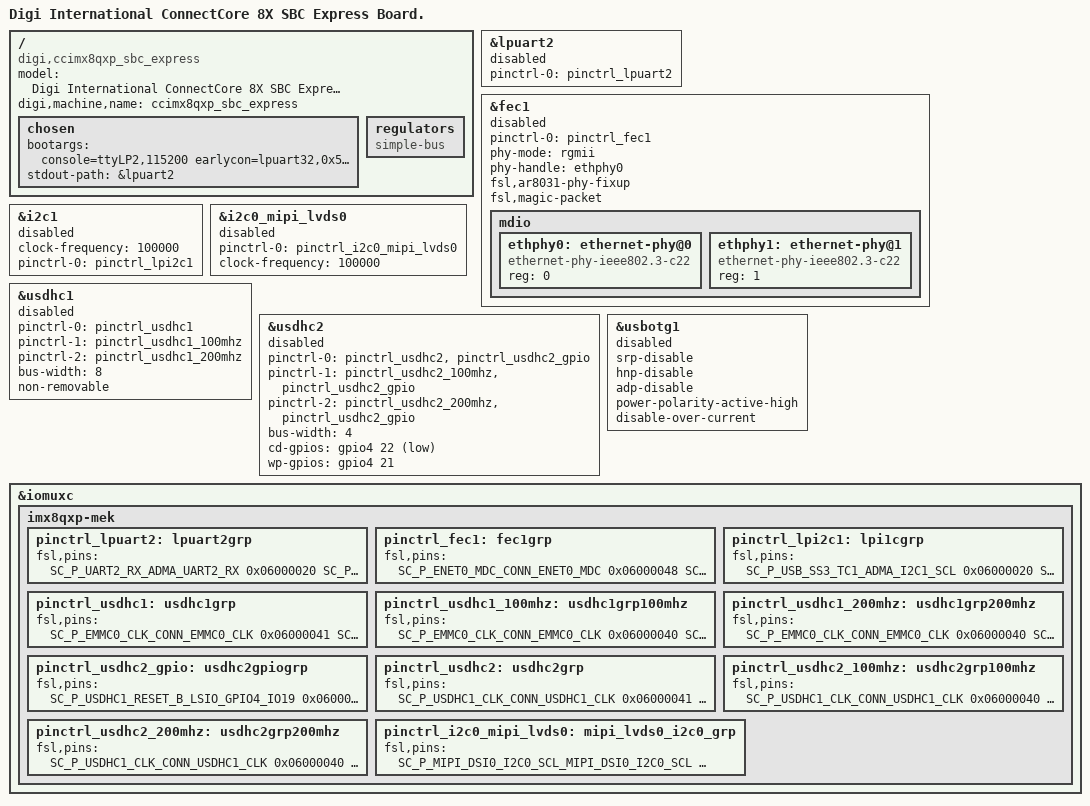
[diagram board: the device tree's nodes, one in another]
/*
 * Copyright 2018 Digi International, Inc.
 *
 * The code contained herein is licensed under the GNU General Public
 * License. You may obtain a copy of the GNU General Public License
 * Version 2 or later at the following locations:
 *
 * http://www.opensource.org/licenses/gpl-license.html
 * http://www.gnu.org/copyleft/gpl.html
 */

/ {
	model = "Digi International ConnectCore 8X SBC Express Board.";
	compatible = "digi,ccimx8qxp_sbc_express", "digi,ccimx8qxp", "fsl,imx8qxp";
	digi,machine,name = "ccimx8qxp_sbc_express";

	chosen {
		bootargs = "console=ttyLP2,115200 earlycon=lpuart32,0x5a080000,115200";
		stdout-path = &lpuart2;
	};

	regulators {
		compatible = "simple-bus";
		#address-cells = <1>;
		#size-cells = <0>;
	};
};

&lpuart2 {
	pinctrl-names = "default";
	pinctrl-0 = <&pinctrl_lpuart2>;
	status = "disabled";
};

&fec1 {
	pinctrl-names = "default";
	pinctrl-0 = <&pinctrl_fec1>;
	phy-mode = "rgmii";
	phy-handle = <&ethphy0>;
	fsl,ar8031-phy-fixup;
	fsl,magic-packet;
	status = "disabled";

	mdio {
		#address-cells = <1>;
		#size-cells = <0>;

		ethphy0: ethernet-phy@0 {
			compatible = "ethernet-phy-ieee802.3-c22";
			reg = <0>;
		};

		ethphy1: ethernet-phy@1 {
			compatible = "ethernet-phy-ieee802.3-c22";
			reg = <1>;
		};
	};
};

&i2c1 {
	#address-cells = <1>;
	#size-cells = <0>;
	clock-frequency = <100000>;
	pinctrl-names = "default";
	pinctrl-0 = <&pinctrl_lpi2c1>;
	status = "disabled";
};

&i2c0_mipi_lvds0 {
	#address-cells = <1>;
	#size-cells = <0>;
	pinctrl-names = "default";
	pinctrl-0 = <&pinctrl_i2c0_mipi_lvds0>;
	clock-frequency = <100000>;
	status = "disabled";
};

&usdhc1 {
	pinctrl-names = "default", "state_100mhz", "state_200mhz";
	pinctrl-0 = <&pinctrl_usdhc1>;
	pinctrl-1 = <&pinctrl_usdhc1_100mhz>;
	pinctrl-2 = <&pinctrl_usdhc1_200mhz>;
	bus-width = <8>;
	non-removable;
	status = "disabled";
};

&usdhc2 {
	pinctrl-names = "default", "state_100mhz", "state_200mhz";
	pinctrl-0 = <&pinctrl_usdhc2>, <&pinctrl_usdhc2_gpio>;
	pinctrl-1 = <&pinctrl_usdhc2_100mhz>, <&pinctrl_usdhc2_gpio>;
	pinctrl-2 = <&pinctrl_usdhc2_200mhz>, <&pinctrl_usdhc2_gpio>;
	bus-width = <4>;
	cd-gpios = <&gpio4 22 GPIO_ACTIVE_LOW>;
	wp-gpios = <&gpio4 21 GPIO_ACTIVE_HIGH>;
	status = "disabled";
};

&usbotg1 {
	srp-disable;
	hnp-disable;
	adp-disable;
	power-polarity-active-high;
	disable-over-current;
	status = "disabled";
};

&iomuxc {
	pinctrl-names = "default";
	imx8qxp-mek {

		pinctrl_lpuart2: lpuart2grp {
			fsl,pins = <
				SC_P_UART2_RX_ADMA_UART2_RX	0x06000020
				SC_P_UART2_TX_ADMA_UART2_TX	0x06000020
			>;
		};

		pinctrl_fec1: fec1grp {
			fsl,pins = <
				SC_P_ENET0_MDC_CONN_ENET0_MDC			0x06000048
				SC_P_ENET0_MDIO_CONN_ENET0_MDIO			0x06000048
				SC_P_ENET0_RGMII_TX_CTL_CONN_ENET0_RGMII_TX_CTL	0x06000048
				SC_P_ENET0_RGMII_TXC_CONN_ENET0_RGMII_TXC	0x06000048
				SC_P_ENET0_RGMII_TXD0_CONN_ENET0_RGMII_TXD0	0x06000048
				SC_P_ENET0_RGMII_TXD1_CONN_ENET0_RGMII_TXD1	0x06000048
				SC_P_ENET0_RGMII_TXD2_CONN_ENET0_RGMII_TXD2	0x06000048
				SC_P_ENET0_RGMII_TXD3_CONN_ENET0_RGMII_TXD3	0x06000048
				SC_P_ENET0_RGMII_RXC_CONN_ENET0_RGMII_RXC	0x06000048
				SC_P_ENET0_RGMII_RX_CTL_CONN_ENET0_RGMII_RX_CTL	0x06000048
				SC_P_ENET0_RGMII_RXD0_CONN_ENET0_RGMII_RXD0	0x06000048
				SC_P_ENET0_RGMII_RXD1_CONN_ENET0_RGMII_RXD1	0x06000048
				SC_P_ENET0_RGMII_RXD2_CONN_ENET0_RGMII_RXD2	0x06000048
				SC_P_ENET0_RGMII_RXD3_CONN_ENET0_RGMII_RXD3	0x06000048
			>;
		};

		pinctrl_lpi2c1: lpi1cgrp {
			fsl,pins = <
				SC_P_USB_SS3_TC1_ADMA_I2C1_SCL	0x06000020
				SC_P_USB_SS3_TC3_ADMA_I2C1_SDA	0x06000020
			>;
		};

		pinctrl_usdhc1: usdhc1grp {
			fsl,pins = <
				SC_P_EMMC0_CLK_CONN_EMMC0_CLK		0x06000041
				SC_P_EMMC0_CMD_CONN_EMMC0_CMD		0x00000021
				SC_P_EMMC0_DATA0_CONN_EMMC0_DATA0	0x00000021
				SC_P_EMMC0_DATA1_CONN_EMMC0_DATA1	0x00000021
				SC_P_EMMC0_DATA2_CONN_EMMC0_DATA2	0x00000021
				SC_P_EMMC0_DATA3_CONN_EMMC0_DATA3	0x00000021
				SC_P_EMMC0_DATA4_CONN_EMMC0_DATA4	0x00000021
				SC_P_EMMC0_DATA5_CONN_EMMC0_DATA5	0x00000021
				SC_P_EMMC0_DATA6_CONN_EMMC0_DATA6	0x00000021
				SC_P_EMMC0_DATA7_CONN_EMMC0_DATA7	0x00000021
				SC_P_EMMC0_STROBE_CONN_EMMC0_STROBE	0x06000041
			>;
		};

		pinctrl_usdhc1_100mhz: usdhc1grp100mhz {
			fsl,pins = <
				SC_P_EMMC0_CLK_CONN_EMMC0_CLK		0x06000040
				SC_P_EMMC0_CMD_CONN_EMMC0_CMD		0x00000020
				SC_P_EMMC0_DATA0_CONN_EMMC0_DATA0	0x00000020
				SC_P_EMMC0_DATA1_CONN_EMMC0_DATA1	0x00000020
				SC_P_EMMC0_DATA2_CONN_EMMC0_DATA2	0x00000020
				SC_P_EMMC0_DATA3_CONN_EMMC0_DATA3	0x00000020
				SC_P_EMMC0_DATA4_CONN_EMMC0_DATA4	0x00000020
				SC_P_EMMC0_DATA5_CONN_EMMC0_DATA5	0x00000020
				SC_P_EMMC0_DATA6_CONN_EMMC0_DATA6	0x00000020
				SC_P_EMMC0_DATA7_CONN_EMMC0_DATA7	0x00000020
				SC_P_EMMC0_STROBE_CONN_EMMC0_STROBE	0x06000040
			>;
		};

		pinctrl_usdhc1_200mhz: usdhc1grp200mhz {
			fsl,pins = <
				SC_P_EMMC0_CLK_CONN_EMMC0_CLK		0x06000040
				SC_P_EMMC0_CMD_CONN_EMMC0_CMD		0x00000020
				SC_P_EMMC0_DATA0_CONN_EMMC0_DATA0	0x00000020
				SC_P_EMMC0_DATA1_CONN_EMMC0_DATA1	0x00000020
				SC_P_EMMC0_DATA2_CONN_EMMC0_DATA2	0x00000020
				SC_P_EMMC0_DATA3_CONN_EMMC0_DATA3	0x00000020
				SC_P_EMMC0_DATA4_CONN_EMMC0_DATA4	0x00000020
				SC_P_EMMC0_DATA5_CONN_EMMC0_DATA5	0x00000020
				SC_P_EMMC0_DATA6_CONN_EMMC0_DATA6	0x00000020
				SC_P_EMMC0_DATA7_CONN_EMMC0_DATA7	0x00000020
				SC_P_EMMC0_STROBE_CONN_EMMC0_STROBE	0x06000040
			>;
		};

		pinctrl_usdhc2_gpio: usdhc2gpiogrp {
			fsl,pins = <
				SC_P_USDHC1_RESET_B_LSIO_GPIO4_IO19	0x06000021
				SC_P_USDHC1_WP_LSIO_GPIO4_IO21		0x06000021
				SC_P_USDHC1_CD_B_LSIO_GPIO4_IO22	0x06000021
			>;
		};

		pinctrl_usdhc2: usdhc2grp {
			fsl,pins = <
				SC_P_USDHC1_CLK_CONN_USDHC1_CLK		0x06000041
				SC_P_USDHC1_CMD_CONN_USDHC1_CMD		0x06000021
				SC_P_USDHC1_DATA0_CONN_USDHC1_DATA0	0x06000021
				SC_P_USDHC1_DATA1_CONN_USDHC1_DATA1	0x06000021
				SC_P_USDHC1_DATA2_CONN_USDHC1_DATA2	0x06000021
				SC_P_USDHC1_DATA3_CONN_USDHC1_DATA3	0x06000021
				SC_P_USDHC1_VSELECT_CONN_USDHC1_VSELECT	0x06000021
			>;
		};

		pinctrl_usdhc2_100mhz: usdhc2grp100mhz {
			fsl,pins = <
				SC_P_USDHC1_CLK_CONN_USDHC1_CLK		0x06000040
				SC_P_USDHC1_CMD_CONN_USDHC1_CMD		0x06000020
				SC_P_USDHC1_DATA0_CONN_USDHC1_DATA0	0x06000020
				SC_P_USDHC1_DATA1_CONN_USDHC1_DATA1	0x06000020
				SC_P_USDHC1_DATA2_CONN_USDHC1_DATA2	0x06000020
				SC_P_USDHC1_DATA3_CONN_USDHC1_DATA3	0x06000020
				SC_P_USDHC1_VSELECT_CONN_USDHC1_VSELECT	0x06000020
			>;
		};

		pinctrl_usdhc2_200mhz: usdhc2grp200mhz {
			fsl,pins = <
				SC_P_USDHC1_CLK_CONN_USDHC1_CLK		0x06000040
				SC_P_USDHC1_CMD_CONN_USDHC1_CMD		0x06000020
				SC_P_USDHC1_DATA0_CONN_USDHC1_DATA0	0x06000020
				SC_P_USDHC1_DATA1_CONN_USDHC1_DATA1	0x06000020
				SC_P_USDHC1_DATA2_CONN_USDHC1_DATA2	0x06000020
				SC_P_USDHC1_DATA3_CONN_USDHC1_DATA3	0x06000020
				SC_P_USDHC1_VSELECT_CONN_USDHC1_VSELECT	0x06000020
			>;
		};

		pinctrl_i2c0_mipi_lvds0: mipi_lvds0_i2c0_grp {
			fsl,pins = <
				SC_P_MIPI_DSI0_I2C0_SCL_MIPI_DSI0_I2C0_SCL 0xc6000020
				SC_P_MIPI_DSI0_I2C0_SDA_MIPI_DSI0_I2C0_SDA 0xc6000020
			>;
		};
	};
};
